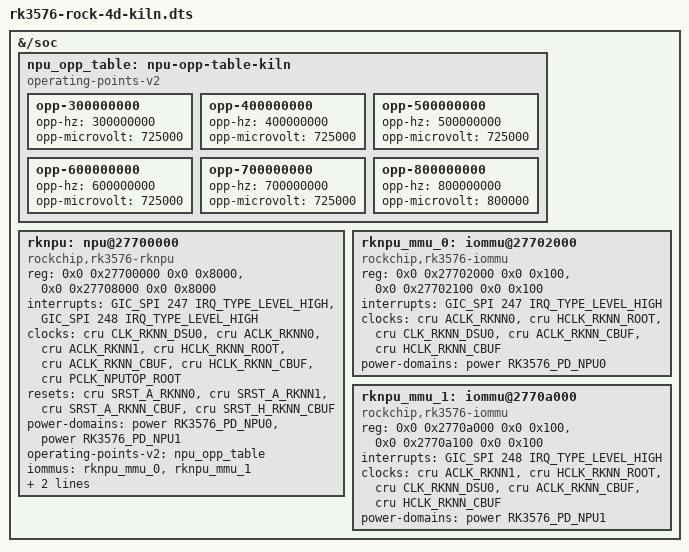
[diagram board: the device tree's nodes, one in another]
// SPDX-License-Identifier: (GPL-2.0-only OR MIT)
/*
 * Kiln board DTS for ROCK 4D: vendor rknpu (v0.9.8) on a mainline kernel.
 * Includes the mainline rock-4d base, removes the open rocket NPU nodes, and
 * adds the single vendor-shaped npu@27700000 + v2 MMU.
 *
 * Bring-up clock = CRU CLK_RKNN_DSU0 fixed rate, NOT SCMI: with devfreq off,
 * SCMI/PVTPLL leaves the NPU with 0 jobs complete (rocket kernel/0019).
 */
#include "rockchip/rk3576-rock-4d.dts"

/delete-node/ &rknn_core_0;
/delete-node/ &rknn_core_1;
/delete-node/ &rknn_mmu_0;
/delete-node/ &rknn_mmu_1;

&{/soc} {
	npu_opp_table: npu-opp-table-kiln {
		compatible = "operating-points-v2";
		opp-300000000 { opp-hz = /bits/ 64 <300000000>; opp-microvolt = <725000>; };
		opp-400000000 { opp-hz = /bits/ 64 <400000000>; opp-microvolt = <725000>; };
		opp-500000000 { opp-hz = /bits/ 64 <500000000>; opp-microvolt = <725000>; };
		opp-600000000 { opp-hz = /bits/ 64 <600000000>; opp-microvolt = <725000>; };
		opp-700000000 { opp-hz = /bits/ 64 <700000000>; opp-microvolt = <725000>; };
		opp-800000000 { opp-hz = /bits/ 64 <800000000>; opp-microvolt = <800000>; };
	};

	rknpu: npu@27700000 {
		compatible = "rockchip,rk3576-rknpu";
		reg = <0x0 0x27700000 0x0 0x8000>,
		      <0x0 0x27708000 0x0 0x8000>;
		interrupts = <GIC_SPI 247 IRQ_TYPE_LEVEL_HIGH>,
			     <GIC_SPI 248 IRQ_TYPE_LEVEL_HIGH>;
		interrupt-names = "npu0_irq", "npu1_irq";
		/*
		 * clk_npu = CRU CLK_RKNN_DSU0 (NOT SCMI: devfreq off, SCMI/PVTPLL gives
		 * 0 jobs per rocket 0019). Do NOT pin assigned-clock-rates: the mainline
		 * composite is GPLL(1188MHz)/N integer divider, so a non-1188/N rate like
		 * 700MHz can't be set cleanly and leaves DSU0 (-> ACLK_RKNN compute clock)
		 * in a bad state -> the register interface (HCLK) still responds but the
		 * compute array never runs -> NPU job timeout, task_counter=0 (observed).
		 * The proven rocket rknn_core node sets NO rate and computes at the CRU
		 * default; match that. Switch to <&scmi_clk 238> once devfreq/DVFS lands.
		 */
		/*
		 * PCLK_NPUTOP_ROOT is REQUIRED and must be kept enabled while the NPU
		 * runs: it clocks the NPU-top control block (the PC/task dispatcher).
		 * The vendor node omits it because the vendor BSP keeps it on elsewhere;
		 * mainline's NPUTOP power-domain only pulses it during the power
		 * transition and then releases it, so without listing it here (so the
		 * driver's devm_clk_bulk_get_all keeps it enabled) the PC never advances
		 * -> NPU job timeout with task_counter=0 (observed). The proven rocket
		 * rknn_core_0 lists it; match that.
		 */
		clocks = <&cru CLK_RKNN_DSU0>, <&cru ACLK_RKNN0>,
			 <&cru ACLK_RKNN1>, <&cru HCLK_RKNN_ROOT>,
			 <&cru ACLK_RKNN_CBUF>, <&cru HCLK_RKNN_CBUF>,
			 <&cru PCLK_NPUTOP_ROOT>;
		clock-names = "clk_npu", "aclk0", "aclk1", "hclk_root",
			      "aclk_cbuf", "hclk_cbuf", "pclk";
		resets = <&cru SRST_A_RKNN0>, <&cru SRST_A_RKNN1>,
			 <&cru SRST_A_RKNN_CBUF>, <&cru SRST_H_RKNN_CBUF>;
		reset-names = "srst_a0", "srst_a1",
			      "srst_a_cbuf", "srst_h_cbuf";
		power-domains = <&power RK3576_PD_NPU0>, <&power RK3576_PD_NPU1>;
		power-domain-names = "npu0", "npu1";
		operating-points-v2 = <&npu_opp_table>;
		/*
		 * Two IOMMU nodes (one per NPU core), NOT a single 4-bank node.
		 * Each MMU carries its own power-domain so that when the rknpu
		 * driver's probe resumes the IOMMU suppliers (pm_runtime_get_suppliers
		 * -> rk_iommu_resume -> rk_iommu_enable), the NPU domain is powered
		 * before the MMU registers are touched. A single 4-bank node spanning
		 * PD_NPU0 + PD_NPU1 cannot do this (genpd auto-attaches only one
		 * domain), and the npu1 banks are accessed while unpowered -> async
		 * SError panic in rk_iommu_is_stall_active. This mirrors the proven
		 * rocket rknn_mmu_0/1 nodes (full 5-clock set + per-core power-domain).
		 */
		iommus = <&rknpu_mmu_0>, <&rknpu_mmu_1>;
		npu-supply = <&vdd_npu_s0>;
		#cooling-cells = <2>;
		dynamic-power-coefficient = <2570>;
		status = "okay";
	};

	rknpu_mmu_0: iommu@27702000 {
		compatible = "rockchip,rk3576-iommu", "rockchip,rk3568-iommu";
		reg = <0x0 0x27702000 0x0 0x100>,
		      <0x0 0x27702100 0x0 0x100>;
		interrupts = <GIC_SPI 247 IRQ_TYPE_LEVEL_HIGH>;
		clocks = <&cru ACLK_RKNN0>, <&cru HCLK_RKNN_ROOT>,
			 <&cru CLK_RKNN_DSU0>, <&cru ACLK_RKNN_CBUF>,
			 <&cru HCLK_RKNN_CBUF>;
		#iommu-cells = <0>;
		power-domains = <&power RK3576_PD_NPU0>;
		status = "okay";
	};

	rknpu_mmu_1: iommu@2770a000 {
		compatible = "rockchip,rk3576-iommu", "rockchip,rk3568-iommu";
		reg = <0x0 0x2770a000 0x0 0x100>,
		      <0x0 0x2770a100 0x0 0x100>;
		interrupts = <GIC_SPI 248 IRQ_TYPE_LEVEL_HIGH>;
		clocks = <&cru ACLK_RKNN1>, <&cru HCLK_RKNN_ROOT>,
			 <&cru CLK_RKNN_DSU0>, <&cru ACLK_RKNN_CBUF>,
			 <&cru HCLK_RKNN_CBUF>;
		#iommu-cells = <0>;
		power-domains = <&power RK3576_PD_NPU1>;
		status = "okay";
	};
};
